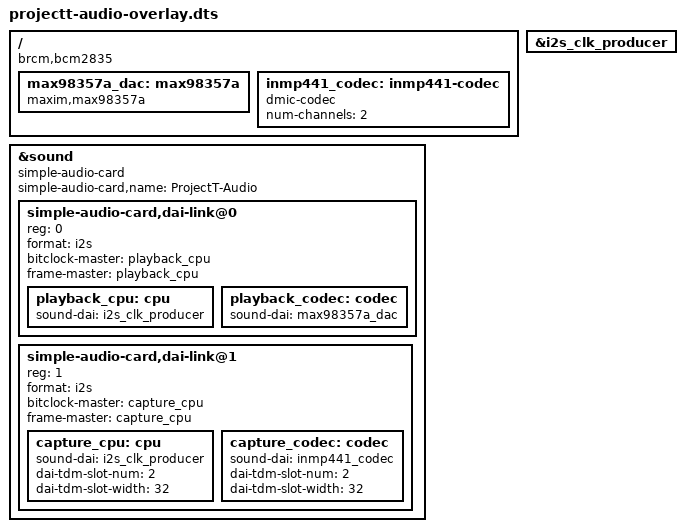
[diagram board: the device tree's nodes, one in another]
/dts-v1/;
/plugin/;

/ {
    compatible = "brcm,bcm2835";

    /*
     * Enable Raspberry Pi I2S controller
     */
    fragment@0 {
        target = <&i2s_clk_producer>;

        __overlay__ {
            status = "okay";
        };
    };

    /*
     * MAX98357A playback codec
     */
    fragment@1 {
        target-path = "/";

        __overlay__ {
            max98357a_dac: max98357a {
                compatible = "maxim,max98357a";
                #sound-dai-cells = <0>;
                status = "okay";
            };
        };
    };

    /*
     * INMP441 capture codec
     *
     * Generic dmic-codec provides the ALSA capture interface.
     */
    fragment@2 {
        target-path = "/";

        __overlay__ {
            inmp441_codec: inmp441-codec {
                compatible = "dmic-codec";
                #sound-dai-cells = <0>;
                num-channels = <2>;
                status = "okay";
            };
        };
    };

    /*
     * Combined Project T sound card
     */
    fragment@3 {
        target = <&sound>;

        __overlay__ {
            compatible = "simple-audio-card";

            #address-cells = <1>;
            #size-cells = <0>;

            simple-audio-card,name = "ProjectT-Audio";
            status = "okay";

            /*
             * PLAYBACK
             * Raspberry Pi I2S -> MAX98357A
             *
             * Pi is I2S clock master.
             */
            simple-audio-card,dai-link@0 {
                reg = <0>;
                format = "i2s";

                bitclock-master = <&playback_cpu>;
                frame-master = <&playback_cpu>;

                playback_cpu: cpu {
                    sound-dai = <&i2s_clk_producer>;
                };

                playback_codec: codec {
                    sound-dai = <&max98357a_dac>;
                };
            };

            /*
             * CAPTURE
             * INMP441 -> Raspberry Pi I2S
             *
             * Pi is I2S clock master.
             */
            simple-audio-card,dai-link@1 {
                reg = <1>;
                format = "i2s";

                bitclock-master = <&capture_cpu>;
                frame-master = <&capture_cpu>;

                capture_cpu: cpu {
                    sound-dai = <&i2s_clk_producer>;
                    dai-tdm-slot-num = <2>;
                    dai-tdm-slot-width = <32>;
                };

                capture_codec: codec {
                    sound-dai = <&inmp441_codec>;
                    dai-tdm-slot-num = <2>;
                    dai-tdm-slot-width = <32>;
                };
            };
        };
    };
};
